# TC37XPD register map
Vendor: Infineon; Series: ATVMC; File version: 100
CPU: other r0p0, little endian, MPU, FPU, vendor SysTick, 4 interrupt priority bits
Registers are 32-bit, read-write, reset 0x0 unless marked. A register's access mark holds for its fields unless they carry their own. Offsets are from the block's base; [hi:lo] are bit positions; lines under a group give offsets from that group; {n}, {i} and the like mark numbered series; 'fields as' and 'values as' point back to an identical list.

## GTM (part 10 of 13)
Base 0xF0100000
{0xE8000+0x800*i} ATOM[{i}] (i=0..5) group
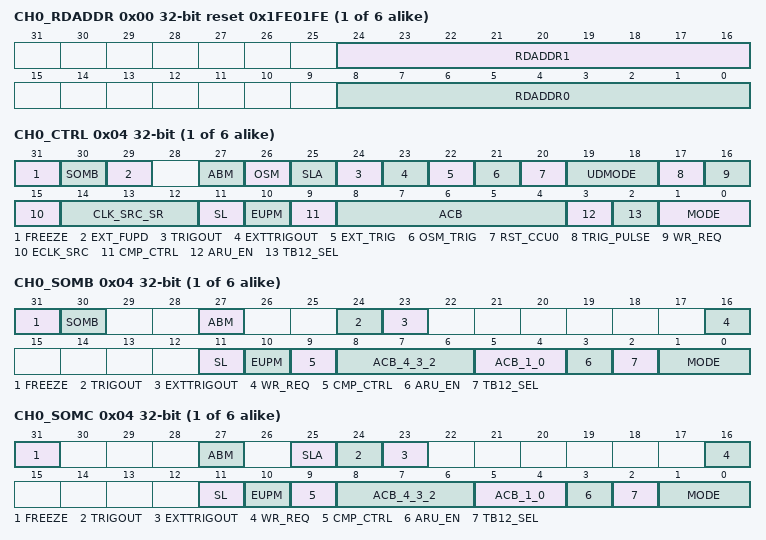
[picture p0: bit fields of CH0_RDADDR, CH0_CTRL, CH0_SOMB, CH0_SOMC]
  0x00 CH0_RDADDR reset 0x1FE01FE — ATOM0 Channel 7 ARU read address Register resetvalue={Application Reset:0x1FE01FE}
    [24:16] RDADDR1 — ARU Read address 1. Note The ATOM channel switches to this read address when requested in the ARU control bits 52 to 48 with the pattern 111 . The channel switches back to the RDADDR0 after one ARU data package was received on RDADDR1 and the compare match event is occurred. Note This read address is only applicable in SOMC mode. Note This bit field is only writable if channel is disabled.
    [8:0] RDADDR0 — ARU Read address 0. Note This read address is used by the ATOM channel to receive data from ARU immediately after the channel and ARU access is enabled see ATOM i CH x CTRL register for details . Note This bit field is only writable if channel is disabled.
  0x04 CH0_CTRL (reset mask 0xFFFFF7FF) — ATOM0 Channel 7 Control Register resetvalue={Application Reset:0x0800,Application Reset:0x0,Application Reset:0x0,Application Reset:0x0,Application Reset:0x0,Application Reset:0x0}
    [31] FREEZE — FREEZE. Note if channel is disabled and ouptut is enabled in SOMP mode with UDMODE 0b00 the output is dependng directly on SL bit independent on FREEZE mode.
    [30] SOMB — SOMB mode
    [29] EXT_FUPD — External forced update. Note This bit is only applicable in SOMP and SOMS mode.
    [27] ABM — ARU blocking mode. Note This bit is only applicable in SOMC and SOMB mode.
    [26] OSM — One shot mode. Note This bit is only applicable in SOMP and SOMS modes.
    [25] SLA — Serve last ARU communication strategy. This bit is only applicable in SOMC mode. Please note that setting of this bit has only effect when ACBI 4 2 is configured for serve last compare strategy 100 101 or 110 . When this bit is not set the captured time stamps in the shadow registers SRx are only provided after the CCU1 match occurred. The ACBO 4 3 bits always return 10 in that case. By setting this bit the ATOM channel also provides the captured time stamps after the CCU0 match event to the ARU. The ACBO 4 3 bits are set to 01 in that case. After the CCU1 match event the time stamps are captured again in the SRx registers and provided to the ARU. The ACBO 4 3 bits are set to 10 . When the data in the shadow registers after the CCU0 match was not consumed by an ARU destination and the CCU1 match occurs the data in the shadow registers is overwritten by the new captured time stamps. The ATOM channel does not request new data from the ARU when the CCU0 match values are read from an ARU destination.
    [24] TRIGOUT — Trigger output selection output signal TRIG CHx of module ATOM CHx
    [23] EXTTRIGOUT — Select TIM EXT CAPTURE x as potential output signal TRIG x
    [22] EXT_TRIG — Select TIM EXT CAPTURE x as trigger signal
    [21] OSM_TRIG — Enable trigger of one shot pulse by trigger signal OSM TRIG. Note This bit should only be set if bit OSM 1 and bit RST CCU0 0.
    [20] RST_CCU0 — Reset source of CCU0. If RST CCU0 1 and UPEN CTRLx 1 are set TRIG x 1 or TIM EXT CAPTURE x triggers also the update of work register CM0 CM1 and CLK SRC . This bit is only applicable in SOMP mode. This bit should only be set if bit OSM 0 i.e. in continuous mode .
    [19:18] UDMODE — Up down counter mode. Note This mode is only applicable in SOMP mode.
    [17] TRIG_PULSE — Trigger output pulse length of one SYS CLK period
    [16] WR_REQ — CPU Write request bit for late compare register update. Note The CPU can disable subsequent ARU read requests by the channel and can update the shadow registers with new compare values while the compare units operate on old compare values received by former ARU accesses if occurred. Note On a compare match event the WR REQ bit will be reset by hardware. Note At the point of the force update only the shadow registers SR0 and SR1 are transferred into the CM0 CM1 registers. The output action is still defined by the ACBI bit field described by the ARU together with the old compare values for CM0 CM1. Note This bit is only applicable in SOMC and SOMB mode.
    [15] ECLK_SRC — Extend CLK SRC. Note This bit is only applicable in SOMP and SOMS mode. See bit CLK SRC SR description for details.
    [14:12] CLK_SRC_SR — Actual CMU clock source SOMS shadow register for CMU clock source SOMP . If ECLK SRC 0 ECLK SRC 1 This register is a shadow register for the register CLK SRC. Thus if the CMU CLK source for PWM generation should be changed during operation the old CMU CLK has to operate until the update of the ATOM channels internal CLK SRC register by the CLK SRC SR content is done either by an end of a period or a forced update. After channel reset the selected CLK SRC value is the SYS CLK input of Global Clock Divider . To use in SOMP mode one of the CMU CLKx it is recommended to perform a forced update of CLK SRC with the value of CLK SRC SR value before with enabling the channel. In case of ECLK SRC 1 and CLK SRC SR 011 100 101 110 a force update leads to an immediate update of CM0 CM1 and CLK SRC.
    [11] SL — Initial signal level. Reset value depends on the hardware configuration chosen by silicon vendor. If the output is disabled the output ATOM OUT x is set to inverse SL independent of the ATOM channel mode. If FREEZE 0 following notes are valid In SOMP SOMI SOMS mode if the channel is disabled the internal register SOUR inside ATOM sub unit SOU is set to inverse value of SL. By enabling the channel the register SOUR is not changed. Thus if the output is enabled afterwards the output ATOM OUT x is the inverse value of SL. In SOMC mode if the channel is disabled the internal register SOUR inside ATOM sub unit SOU is set to value of SL. By enabling the channel the register SOUR is not changed. Thus if the output is enabled and the channel is disabled the output ATOM OUT x is the value of SL. If FREEZE 1 the following notes are valid If the channel is disabled the output register of SOU unit is not changed and output ATOM OUT x is not changed.
    [10] EUPM — Extended update mode. If EUPM 1 a write access to CM0 or CM1 never causes an AEI write status 10 . This bit is only applicable in SOMC and SOMB mode.
    [9] CMP_CTRL — CCUx compare strategy select. Note This bit is only applicable in SOMC mode.
    [8:4] ACB — ATOM Mode control bits. These bits have different meaning in the different ATOM channel modes. Please refer to the mode description sections. SOMI CROSSREFERENCE and CROSSREFERENCE for register description. SOMC CROSSREFERENCE and CROSSREFERENCE for register description. SOMP CROSSREFERENCE and CROSSREFERENCE for register description. SOMS CROSSREFERENCE and CROSSREFERENCE for register description. SOMB CROSSREFERENCE and CROSSREFERENCE for register description.
    [3] ARU_EN — ARU input stream enable
    [2] TB12_SEL — Select time base value TBU TS1 or TBU TS2. Note This bit is only applicable in SOMC mode.
    [1:0] MODE — ATOM channel mode select
  0x04 CH0_SOMB (reset mask 0xFFFFF7FF) — ATOM0 Channel 7 Control Register in SOMB Mode resetvalue={Application Reset:0x0800,Application Reset:0x0,Application Reset:0x0,Application Reset:0x0,Application Reset:0x0,Application Reset:0x0}
    [31] FREEZE
    [30] SOMB — SOMB SOMB mode
    [27] ABM — ARU blocking mode
    [24] TRIGOUT — Trigger output selection output signal TRIG CHx of module ATOM CHx
    [23] EXTTRIGOUT — TIM EXT CAPTURE x as potential output signal TRIG x
    [16] WR_REQ — CPU Write request bit for late compare register update. The CPU can disable subsequent ARU read requests by the channel and can update the shadow registers with new compare values while the compare units operate on old compare values received by former ARU accesses if occurred. On a compare match event the WR REQ bit will be reset by hardware. At the point of the force update only the shadow registers SR0 and SR1 are transferred into the CM0 CM1 registers. The output action is still defined by the ACBI bit field described by the ARU together with the old compare values for CM0 CM1.
    [11] SL — Initial signal level after channel enable. Reset value depends on the hardware configuration chosen by silicon vendor. If the output is disabled the output ATOM OUT x is set to inverse value of SL. If FREEZE 0 the following note is valid If the channel is disabled the output register of SOU unit is set to value of SL. If FREEZE 1 the following note is valid If the channel is disabled the output register of SOU unit is not changed and output ATOM OUT x is not changed.
    [10] EUPM — Extended update mode. If EUPM 1 and after a CCU0 compare match if ARU EN 0 written CM0 value not stored. if ARU EN 1 ARU read request is continued and CM1 is updated until CCU1 compare match. Received CM0 is not stored. This bit is only applicable in SOMC and SOMB mode.
    [9] CMP_CTRL — CCUx compare strategy select. The compare unit CCU0 or CCU1 that compares against TBU TS0 depending on CCUx control mode defined by ACB CM 4 2 always performs a greater equal comparison independent of the CMP CTRL bit.
    [8:6] ACB_4_3_2 — ATOM SOMB compare strategy. These bits are only applicable if ARU EN 0.
    [5:4] ACB_1_0 — Signal level control bits. Note These bits are only applicable if ARU EN 0.
    [3] ARU_EN — ARU Input stream enable
    [2] TB12_SEL — Select time base value TBU TS1 or TBU TS2. This bit is only applicable if three time bases are present in the GTM. Otherwise this bit is reserved.
    [1:0] MODE — ATOM channel mode select. Not used in ATOM SOMB mode.
  0x04 CH0_SOMC (reset mask 0xFFFFF7FF) — ATOM0 Channel 7 Control Register in SOMC Mode resetvalue={Application Reset:0x0800,Application Reset:0x0,Application Reset:0x0,Application Reset:0x0,Application Reset:0x0,Application Reset:0x0}
    [31] FREEZE
    [27] ABM — ARU blocking mode
    [25] SLA — Serve last ARU communication strategy. Please note that setting of this bit has only effect when ACBI 4 2 is configured for serve last compare strategy quot 100 quot quot 101 quot or quot 110 quot . When this bit is not set the captured time stamps in the shadow registers SRx are only provided after the CCU1 match occurred. The ACBO 4 3 bits always return quot 10 quot in that case. By setting this bit the ATOM channel also provides the captured time stamps after the CCU0 match event to the ARU. The ACBO 4 3 bits are set to 8220 01 8221 in that case. After the CCU1 match event the time stamps are captured again in the SRx registers and provided to the ARU. The ACBO 4 3 bits are set to 8220 10 8221 . When the data in the shadow registers after the CCU0 match was not consumed by an ARU destination and the CCU1 match occurs the data in the shadow registers is overwritten by the new captured time stamps. The ATOM channel does not request new data from the ARU when the CCU0 match values are read from an ARU destination.
    [24] TRIGOUT — TRIGOUT Trigger output selection output signal TRIG CHx of module ATOM CHx
    [23] EXTTRIGOUT — Select TIM EXT CAPTURE x as potential output signal TRIG x
    [16] WR_REQ — CPU write request bit. The CPU can disable subsequent ARU read requests by the channel and can update the shadow registers with new compare values while the compare units operate on old compare values received by former ARU accesses if occurred. On a compare match event the WR REQ bit will be reset by hardware. At the point of the force update only the shadow registers SR0 and SR1 are transferred into the CM0 CM1 registers. The output action is still defined by the ACBI bit field described by the ARU together with the old compare values for CM0 CM1.
    [11] SL — Initial signal level after channel enable. Reset value depends on the hardware configuration chosen by silicon vendor. If the output is disabled the output ATOM OUT x is set to inverse value of SL. If FREEZE 0 following note is valid If the channel is disabled the output register of SOU unit is set to value of SL. If FREEZE 1 following note is valid If the channel is disabled the output register of SOU unit is not changed and output ATOM OUT x is not changed.
    [10] EUPM — Extended Update Mode. If EUPM 1 and after a CCU0 compare match If ARU EN 0 written CM0 value not stored. If ARU EN 1 ARU read request is continued and CM1 is updated until CCU1 compare match. Received CM0 values are not stored. This bit is only applicable in SOMC and SOMB mode.
    [9] CMP_CTRL — CCUx compare strategy select. The compare unit CCU0 or CCU1 that compares against TBU TS0 depending on CCUx control mode defined by ACBI 4 2 or ACB42 always performs a greater equal comparison independent on CMP CTRL bit.
    [8:6] ACB_4_3_2 — ATOM control bits ACB 4 ACB 3 ACB 2 . Independent of ARU EN a writing of 0b111 cancels any pending CCU0 or CCU1 compare. Note These bits are defining the compare strategy only if ARU EN 0.
    [5:4] ACB_1_0 — Signal level control bits. These bits are only applicable if ARU EN 0.
    [3] ARU_EN — ARU Input stream enable
    [2] TB12_SEL — Select time base value TBU TS1 or TBU TS2. This bit is only applicable if three time bases are present in the GTM. Otherwise this bit is reserved.
    [1:0] MODE — ATOM channel mode select
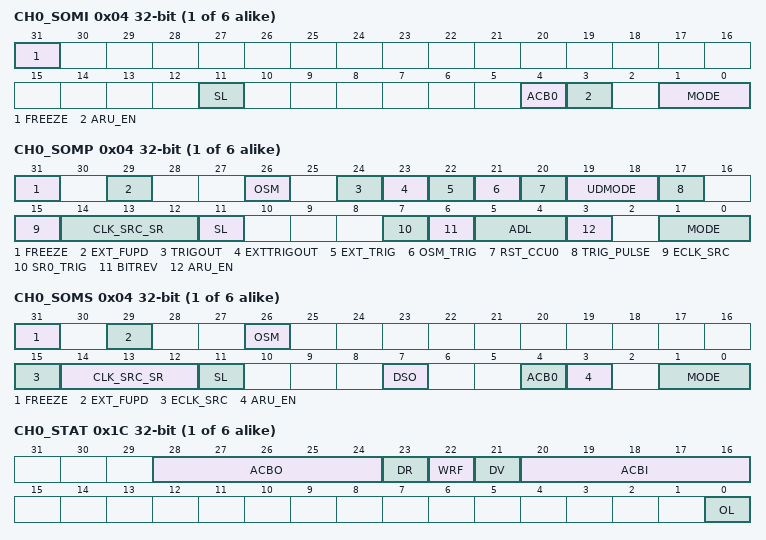
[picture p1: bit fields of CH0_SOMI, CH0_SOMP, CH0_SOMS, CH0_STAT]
  0x04 CH0_SOMI (reset mask 0xFFFFF7FF) — ATOM0 Channel 7 Control Register in SOMI Mode resetvalue={Application Reset:0x0800,Application Reset:0x0,Application Reset:0x0,Application Reset:0x0,Application Reset:0x0,Application Reset:0x0}
    [31] FREEZE
    [11] SL — Initial signal level after channel is enabled. Note Reset value depends on the hardware configuration chosen by silicon vendor. Note If the output is disabled the output ATOM OUT x is set to inverse value of SL. If FREEZE 0 following note is valid If the channel is disabled the output register of SOU unit is set to inverse value of SL. If FREEZE 1 following note is valid If the channel is disabled the output register of SOU unit is not changed and output ATOM OUT x is not changed.
    [4] ACB0 — ACB bit 0 . Note Bosch name ACB 0 .
    [3] ARU_EN — ARU Input stream enable
    [1:0] MODE — ATOM channel mode select
  0x04 CH0_SOMP (reset mask 0xFFFFF7FF) — ATOM0 Channel 7 Control Register in SOMP Mode resetvalue={Application Reset:0x0800,Application Reset:0x0,Application Reset:0x0,Application Reset:0x0,Application Reset:0x0,Application Reset:0x0}
    [31] FREEZE
    [29] EXT_FUPD — External forced update. This bit is only applicable in SOMP and SOMS mode.
    [26] OSM — One shot mode
    [24] TRIGOUT — Trigger output selection output signal TRIG CHx of module ATOM CHx
    [23] EXTTRIGOUT — Select TIM EXT CAPTURE x as potential output signal TRIG x
    [22] EXT_TRIG — Select TIM EXT CAPTURE x as trigger signal
    [21] OSM_TRIG — Enable trigger of one shot pulse by trigger signal OSM TRIG. This bit should only be set if bit OSM 1 and bit RST CCU0 0.
    [20] RST_CCU0 — Reset source of CCU0. If RST CCU0 1 and UPEN CTRLx 1 are set TRIG x 1 or TIM EXT CAPTURE x triggers also the update of work register CM0 CM1 and CLK SRC .
    [19:18] UDMODE — Up down counter mode. This mode is only applicable in SOMP mode.
    [17] TRIG_PULSE — Trigger output pulse length of one SYS CLK period
    [15] ECLK_SRC — Extend CLK SRC. See bit CLK SRC SR description for details.
    [14:12] CLK_SRC_SR — Shadow register for CMU clock source register CLK SRC. If ECLK SRC 0 ECLK SRC 1 This register is a shadow register for the register CLK SRC. Thus if the CMU CLK source for PWM generation should be changed during operation the old CMU CLK has to operate until the update of the ATOM channels internal CLK SRC register by the CLK SRC SR content is done either by an end of a period or a FORCE UPDATE. After channel reset the selected CLK SRC value is the SYS CLK input of Global Clock Divider . To use in SOMP mode one of the CMU CLKx it is recommended to perform a forced update of CLK SRC with the value of CLK SRC SR value before with enabling the channel.
    [11] SL — Signal level for pulse of PWM. Reset value depends on the hardware configuration chosen by silicon vendor. If the output is disabled the output ATOM OUT x is set to inverse value of SL FREEZE 0 the following note is valid If the channel is disabled the output register of SOU unit is set to inverse value of SL. If FREEZE 1 the following note is valid If the channel is disabled the output register of SOU unit is not changed and output ATOM OUT x is not changed.
    [7] SR0_TRIG — SR0 is used to generate a trigger on output ATOM i CH x OUT T if equal to CN0. This bit is only relevant in SOMP mode. This bit should only be set if RST CCU0 of this channel is 0.
    [6] BITREV — Bit reversing of output of counter register CN0. This bit enables the PCM mode. It is device specific in which channel the PCM mode is available. Please refer to device specific CROSSREFERENCE for this information.
    [5:4] ADL — ARU data select for SOMP. This bit field is only relevant in SOMP mode to select the ARU data source.
    [3] ARU_EN — ARU Input stream enable
    [1:0] MODE — ATOM channel mode select
  0x04 CH0_SOMS (reset mask 0xFFFFF7FF) — ATOM0 Channel 7 Control Register in SOMS Mode resetvalue={Application Reset:0x0800,Application Reset:0x0,Application Reset:0x0,Application Reset:0x0,Application Reset:0x0,Application Reset:0x0}
    [31] FREEZE
    [29] EXT_FUPD — External forced update. This bit is only applicable in SOMP and SOMS mode.
    [26] OSM — One shot mode
    [15] ECLK_SRC — Extend CLK SRC. See bit CLK SRC SR description for details.
    [14:12] CLK_SRC_SR — Shift frequency select for channel. If ECLK SRC 0 ECLK SRC 1 This register is a shadow register for the register CLK SRC. Thus if the CMU CLK source for PWM generation should be changed during operation the old CMU CLK has to operate until the update of the ATOM channels internal CLK SRC register by the CLK SRC SR content is done either by an end of a period or a FORCE UPDATE. After channel reset the selected CLK SRC value is the SYS CLK input of Global Clock Divider . To use in SOMP mode one of the CMU CLKx it is recommended to perform a forced update of CLK SRC with the value of CLK SRC SR value before with enabling the channel.
    [11] SL — Defines signal level when channel and output is disabling. Reset value depends on the hardware configuration chosen by silicon vendor. If the output is enabled the output ATOM OUT x is set to bit 0 or 23 of CM1 register. If the output is disabled the output ATOM OUT x is set to inverse value of SL. An enable or disable of the channel x has no effect on ATOM OUT x . The inverse value of SL is shifted into the CM1 register. If FREEZE 0 the following note is valid If the channel is disabled the output register of SOU unit is set to inverse value of SL. If FREEZE 1 the following note is valid If the channel is disabled the output register of SOU unit is not changed and output ATOM OUT x is not changed.
    [7] DSO — Double Shift Output. Note If DSO 1 only shift right is possible.
    [4] ACB0 — Shift direction for CM1 register. The data that has to be shifted out has to be aligned inside the CM1 register according to the defined shift direction. This bit is only applicable if ARU EN 0. If the direction ACB0 is changed the output ATOM OUT x switches immediately to the other first bit of CM1 bit 0 if ACB0 0 bit 23 if ACB0 160 160 1 .
    [3] ARU_EN — ARU Input stream enable
    [1:0] MODE — ATOM channel mode select
  0x08 CH0_SR0 — ATOM0 Channel 7 CCU0 Compare Shadow Register resetvalue={Application Reset:0x0}
    [23:0] SR0 — ATOM channel x shadow register SR0. Note The SR0 register is used as shadow register for CM0 in SOMP and SOMS modes and is used as capture register for time base TBU TS0 in SOMC mode.
  0x0C CH0_SR1 — ATOM0 Channel 7 CCU1 Compare Shadow Register resetvalue={Application Reset:0x0}
    [23:0] SR1 — ATOM channel x shadow register SR1. Note The SR1 register is used as shadow register for CM1 in SOMP and SOMS modes and is used as capture register for time base TBU TS1 or TBU TS2 when selected in ATOM i CH x CTRL register in SOMC mode.
  0x10 CH0_CM0 — ATOM0 Channel 7 CCU0 Compare Register resetvalue={Application Reset:0x0}
    [23:0] CM0 — ATOM CCU0 compare register
  0x14 CH0_CM1 — ATOM0 Channel 7 CCU1 Compare Register resetvalue={Application Reset:0x0}
    [23:0] CM1 — ATOM CCU1 compare register
  0x18 CH0_CN0 — ATOM0 Channel 7 CCU0 Counter Register resetvalue={Application Reset:0x0}
    [23:0] CN0 — ATOM CCU0 counter register
  0x1C CH0_STAT access per field — ATOM0 Channel 7 Status Register resetvalue={Application Reset:0x0}
    [28:24] ACBO ro — ATOM Internal status bits. ACBO 3 1 CCU0 Compare match occurred. ACBO 4 1 CCU1 Compare match occurred. Note These bits are only set in SOMC mode. Note ACBO is reset to 0b00000 on an update of register CM0 or CM1 via ARU or CPU . Note In SOMC mode these bits are sent as ARU control bits 52..48.
    [23] DR ro — ARU data rejected flag. Note The flag is cleared if valid data is received and stored via ARU.
    [22] WRF rw — Write request of CPU failed for late update. Note This bit is only applicable in SOMC and SOMB mode. Bit WRF can be reset by writing a 1 to it.
    [21] DV ro — Valid ARU Data stored in compare registers. Note This bit is only applicable in SOMC and SOMB mode. The CPU can determine the status of the ARU transfers with this bit. After the compare event occurred the bit is reset by hardware .
    [20:16] ACBI ro — ATOM Mode control bits. Note For ATOM SOMI SOMC SOMP and SOMS mode this register serves as a mirror for the five ARU control bits received through the ARU interface. The bits are valid when the DV bit is set. Note For SOMB mode this bit field serves as the work register of the compare strategy. It can be updated with the value of bit field ACB of register ATOM i CH x CTRL or the value of internal shadow register ACB SR.
    [0] OL ro — Actual output signal level of ATOM CHx OUT. Note Reset value is the inverted value of bit SL which depends on the hardware configuration chosen by silicon vendor.
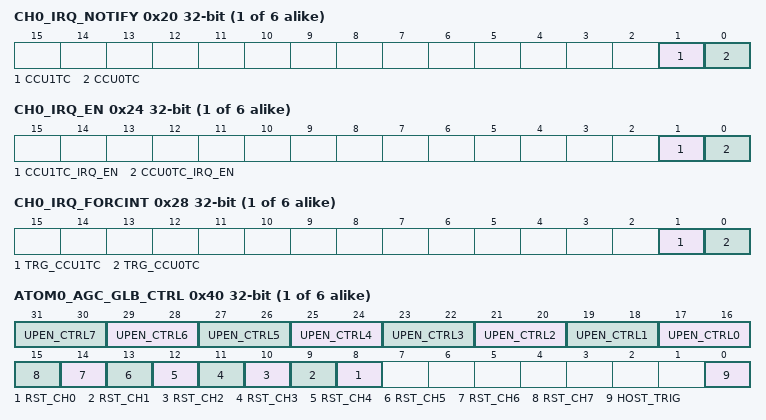
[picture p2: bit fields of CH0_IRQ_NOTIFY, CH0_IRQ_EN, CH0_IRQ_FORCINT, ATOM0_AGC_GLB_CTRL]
  0x20 CH0_IRQ_NOTIFY — ATOM0 Channel 7 Interrupt Notification Register resetvalue={Application Reset:0x0}
    [1] CCU1TC — CCU1TC CCU1 Trigger condition interrupt for channel x. The notification of the interrupt is only triggered one time after reaching the condition CN0 gt CM1. To enable re trigger of the notification first the condition CN0 lt CM1 has to be reached. Note This bit will be cleared on a CPU write access of value 1. A read access leaves the bit unchanged. Note This description differs to the description in the Bosch spec. Note If bit SR0 TRIG is set to 1 only valid in SOMP mode this interrupt notify flag is set in case of SR0 is equal to CN0 and not set in case of CM1 gt lt CN0.
    [0] CCU0TC — CCU0 Trigger condition interrupt for channel x. The notification of the interrupt is only triggered one time after reaching the condition CN0 gt CM0. To enable re trigger of the notification first the condition CN0 lt CM1 has to be reached. Note This bit will be cleared on a CPU write access of value 1. A read access leaves the bit unchanged. Note This description differs to the description in the Bosch spec.
  0x24 CH0_IRQ_EN — ATOM0 Channel 7 Interrupt Enable Register resetvalue={Application Reset:0x0}
    [1] CCU1TC_IRQ_EN — ATOM CCU1TC IRQ interrupt enable. See bit 0.
    [0] CCU0TC_IRQ_EN — ATOM CCU0TC IRQ interrupt enable
  0x28 CH0_IRQ_FORCINT — ATOM0 Channel 7 Software Interrupt Generation Register resetvalue={Application Reset:0x0}
    [1] TRG_CCU1TC — Trigger ATOM CCU1TC IRQ interrupt by software. Note This bit is cleared automatically after write. Note This bit is write protected by bit RF PROT of register GTM CTRL
    [0] TRG_CCU0TC — Trigger ATOM CCU0TC IRQ interrupt by software. Note This bit is cleared automatically after write. Note This bit is write protected by bit RF PROT of register GTM CTRL
  0x2C CH0_IRQ_MODE — ATOM0 Channel 7 Interrupt Mode Configuration Register resetvalue={Application Reset:0x0}
    [1:0] IRQ_MODE — IRQ mode selection. Note The interrupt modes are described in CROSSREFERENCE .
  0x40 ATOM0_AGC_GLB_CTRL access per field — ATOM0 AGC Global Control Register resetvalue={Application Reset:0x0}
    [2n+17:2n+16] UPEN_CTRL{n} rw (n=0..7) — ATOM channel 7 enable update of register CM0 CM1 and CLK SRC from SR0 SR1 and CLK SRC SR. Write Read
    [n+8] RST_CH{n} wo (n=0..7) — Software reset of channel 7. Note This bit is cleared automatically after write by CPU. The channel registers are set to their reset values and channel operation is stopped immediately. The output register of SOU unit is reset to inverse reset value of SL bit.
    [0] HOST_TRIG wo — Trigger request signal see AGC to update the register ENDIS STAT and OUTEN STAT. Note this flag is reset automatically after triggering the update
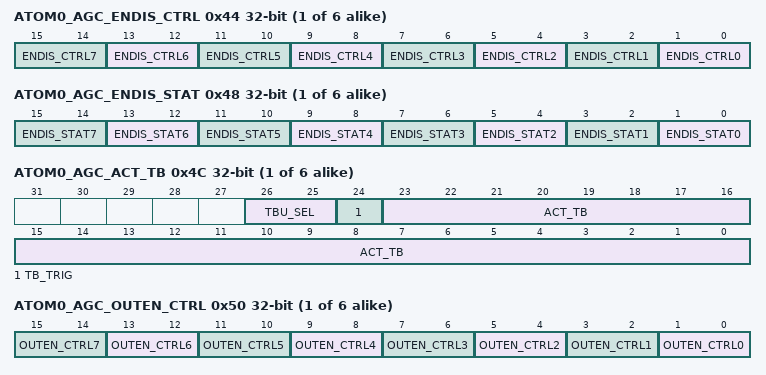
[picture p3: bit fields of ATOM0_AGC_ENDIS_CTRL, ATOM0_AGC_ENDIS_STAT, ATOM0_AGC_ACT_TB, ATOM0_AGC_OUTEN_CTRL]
  0x44 ATOM0_AGC_ENDIS_CTRL — ATOM0 AGC Enable Disable Control Register resetvalue={Application Reset:0x0}
    [2n+1:2n] ENDIS_CTRL{n} (n=0..7) — ATOM channel 7 enable disable update value. If FREEZE 0 and an ATOM channel is disabled the counter CN0 is stopped and the output register of SOU unit is set to the inverse value of control bit SL. On an enable event the counter CN0 starts counting from its current value. If FREEZE 1 and an ATOM channel is disabled the counter CN0 is stopped SOMP SOMS mode and each comparison is stopped SOMC SOMB mode . On an enable event the counter CN0 starts counting from its current value or a comparison is restarted. Write of following double bit values is possible Note If the output is disabled OUTEN x 0 the ATOM channel x output ATOM OUT x is the inverted value of bit SL.
  0x48 ATOM0_AGC_ENDIS_STAT — ATOM0 AGC Enable Disable Status Register resetvalue={Application Reset:0x0}
    [2n+1:2n] ENDIS_STAT{n} (n=0..7) — ATOM channel 7 enable disable. If FREEZE 0 and an ATOM channel is disabled the counter CN0 is stopped and the output register of SOU unit is set to the inverse value of control bit SL. On an enable event the counter CN0 starts counting from its current value. If FREEZE 1 and an ATOM channel is disabled the counter CN0 is stopped SOMP SOMS mode and each comparison is stopped SOMC SOMB mode . On an enable event the counter CN0 starts counting from its current value or a comparison is restarted.
  0x4C ATOM0_AGC_ACT_TB — ATOM0 AGC Action Time Base Register resetvalue={Application Reset:0x0}
    [26:25] TBU_SEL — Selection of time base used for comparison. Note The bit combination 0b10 is only applicable if the TBU of the device contains three time base channels. Otherwise this bit combination is also reserved. Please refer to GTM Architecture block diagram on page 3 to determine the number of channels for TBU of this device.
    [24] TB_TRIG — Set trigger request. Note This flag is reset automatically if the selected time base unit TBU TS0 or TBU TS1 or TBU TS2 if present has reached the value ACT TB and the update of the register was triggered.
    [23:0] ACT_TB — Time base value. Specifies the signed compare value with selected signal TBU TS x x 0..2. If selected TBU TS x value is in the interval ACT TB 007FFFFFh ACT TB the event is in the past and the trigger is generated immediately. Otherwise the event is in the future and the trigger is generated if selected TBU TS x is equal to ACT TB.
  0x50 ATOM0_AGC_OUTEN_CTRL — ATOM0 AGC Output Enable Control Register resetvalue={Application Reset:0x0}
    [2n+1:2n] OUTEN_CTRL{n} (n=0..7) — Output ATOM OUT7 enable disable update value. Write of following double bit values is possible Note If the channel is disabled ENDIS 0 0 or the output is disabled OUTEN 0 0 the TOM channel 0 output ATOM OUT 0 is the inverted value of bit SL.
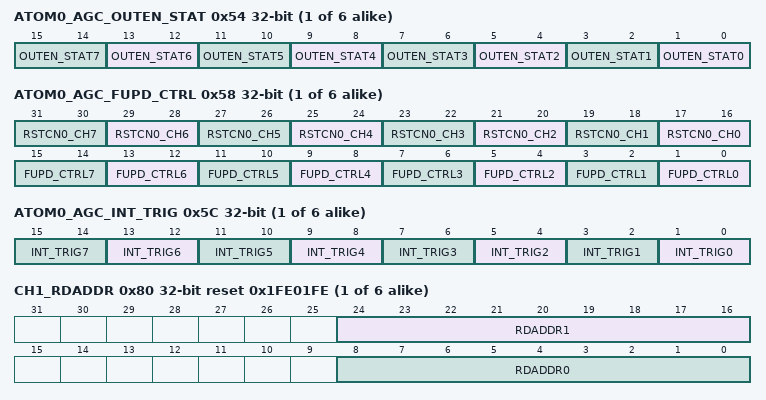
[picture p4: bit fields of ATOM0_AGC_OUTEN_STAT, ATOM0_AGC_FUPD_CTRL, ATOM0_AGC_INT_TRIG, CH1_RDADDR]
  0x54 ATOM0_AGC_OUTEN_STAT — ATOM0 AGC Output Enable Status Register resetvalue={Application Reset:0x0}
    [2n+1:2n] OUTEN_STAT{n} (n=0..7) — Control status of output ATOM OUT7. Write Read
  0x58 ATOM0_AGC_FUPD_CTRL — ATOM0 AGC Force Update Control Register resetvalue={Application Reset:0x0}
    [2n+17:2n+16] RSTCN0_CH{n} (n=0..7) — Reset CN0 of channel 7 on force update event. If enabled reset CN0 triggered by HOST TRIG ACT TB compare match or internal trigger. Write Read
    [2n+1:2n] FUPD_CTRL{n} (n=0..7) — Force update of ATOM channel 7 operation registers. If enabled force update of register CM0 CM1 and CLK SRC triggered by HOST TRIG ACT TB compare match or internal trigger. Write Read Note In SOMP mode the force update request is stored and executed synchronized to the selected CMU CLK. In all other modes the force update request is executed immediately. Note In SOMP mode in case of ECLK SRC 1 and CLK SRC SR 0b011 0b100 0b101 0b110 a force update leads to an immediate update of CM0 CM1 and CLK SRC.
  0x5C ATOM0_AGC_INT_TRIG — ATOM0 AGC Internal Trigger Control Register resetvalue={Application Reset:0x0}
    [2n+1:2n] INT_TRIG{n} (n=0..7) — Select input signal TRIG 7 as a trigger source. Write Read
  0x80 CH1_RDADDR reset 0x1FE01FE — ATOM0 Channel 7 ARU read address Register resetvalue={Application Reset:0x1FE01FE}
    fields as ATOM[0].CH0_RDADDR
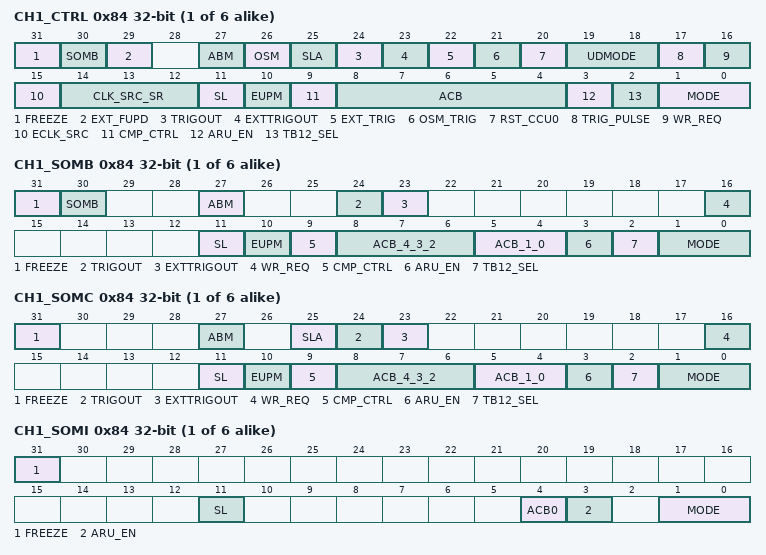
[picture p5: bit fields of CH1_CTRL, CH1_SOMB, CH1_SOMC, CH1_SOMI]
  0x84 CH1_CTRL (reset mask 0xFFFFF7FF) — ATOM0 Channel 7 Control Register resetvalue={Application Reset:0x0800,Application Reset:0x0,Application Reset:0x0,Application Reset:0x0,Application Reset:0x0,Application Reset:0x0}
    fields as ATOM[0].CH0_CTRL
  0x84 CH1_SOMB (reset mask 0xFFFFF7FF) — ATOM0 Channel 7 Control Register in SOMB Mode resetvalue={Application Reset:0x0800,Application Reset:0x0,Application Reset:0x0,Application Reset:0x0,Application Reset:0x0,Application Reset:0x0}
    fields as ATOM[0].CH0_SOMB
  0x84 CH1_SOMC (reset mask 0xFFFFF7FF) — ATOM0 Channel 7 Control Register in SOMC Mode resetvalue={Application Reset:0x0800,Application Reset:0x0,Application Reset:0x0,Application Reset:0x0,Application Reset:0x0,Application Reset:0x0}
    fields as ATOM[0].CH0_SOMC
  0x84 CH1_SOMI (reset mask 0xFFFFF7FF) — ATOM0 Channel 7 Control Register in SOMI Mode resetvalue={Application Reset:0x0800,Application Reset:0x0,Application Reset:0x0,Application Reset:0x0,Application Reset:0x0,Application Reset:0x0}
    fields as ATOM[0].CH0_SOMI
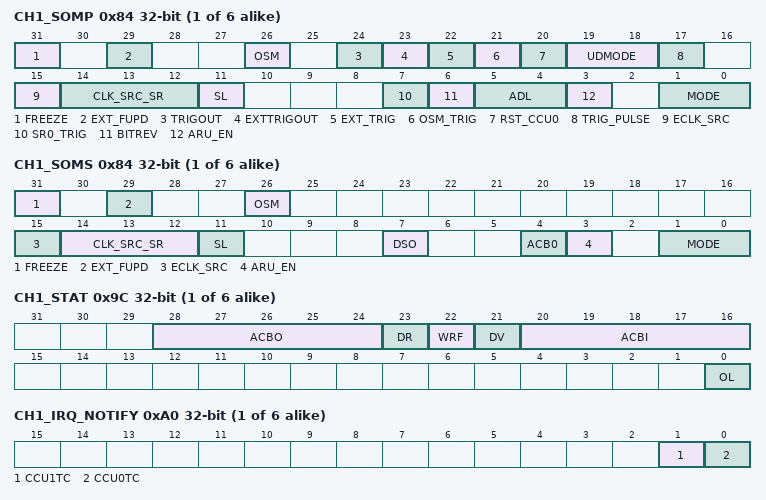
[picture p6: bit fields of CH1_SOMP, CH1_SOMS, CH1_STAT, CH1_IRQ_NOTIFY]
  0x84 CH1_SOMP (reset mask 0xFFFFF7FF) — ATOM0 Channel 7 Control Register in SOMP Mode resetvalue={Application Reset:0x0800,Application Reset:0x0,Application Reset:0x0,Application Reset:0x0,Application Reset:0x0,Application Reset:0x0}
    fields as ATOM[0].CH0_SOMP
  0x84 CH1_SOMS (reset mask 0xFFFFF7FF) — ATOM0 Channel 7 Control Register in SOMS Mode resetvalue={Application Reset:0x0800,Application Reset:0x0,Application Reset:0x0,Application Reset:0x0,Application Reset:0x0,Application Reset:0x0}
    fields as ATOM[0].CH0_SOMS
  0x88 CH1_SR0 — ATOM0 Channel 7 CCU0 Compare Shadow Register resetvalue={Application Reset:0x0}
    fields as ATOM[0].CH0_SR0
  0x8C CH1_SR1 — ATOM0 Channel 7 CCU1 Compare Shadow Register resetvalue={Application Reset:0x0}
    fields as ATOM[0].CH0_SR1
  0x90 CH1_CM0 — ATOM0 Channel 7 CCU0 Compare Register resetvalue={Application Reset:0x0}
    [23:0] CM0 — ATOM CCU0 compare register
  0x94 CH1_CM1 — ATOM0 Channel 7 CCU1 Compare Register resetvalue={Application Reset:0x0}
    [23:0] CM1 — ATOM CCU1 compare register
  0x98 CH1_CN0 — ATOM0 Channel 7 CCU0 Counter Register resetvalue={Application Reset:0x0}
    [23:0] CN0 — ATOM CCU0 counter register
  0x9C CH1_STAT access per field — ATOM0 Channel 7 Status Register resetvalue={Application Reset:0x0}
    fields as ATOM[0].CH0_STAT
  0xA0 CH1_IRQ_NOTIFY — ATOM0 Channel 7 Interrupt Notification Register resetvalue={Application Reset:0x0}
    fields as ATOM[0].CH0_IRQ_NOTIFY
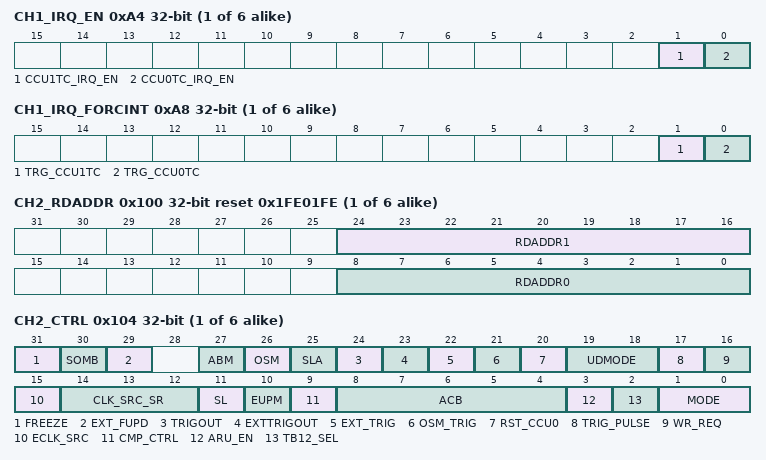
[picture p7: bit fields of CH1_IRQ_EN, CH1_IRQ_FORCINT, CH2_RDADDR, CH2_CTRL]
  0xA4 CH1_IRQ_EN — ATOM0 Channel 7 Interrupt Enable Register resetvalue={Application Reset:0x0}
    fields as ATOM[0].CH0_IRQ_EN
  0xA8 CH1_IRQ_FORCINT — ATOM0 Channel 7 Software Interrupt Generation Register resetvalue={Application Reset:0x0}
    fields as ATOM[0].CH0_IRQ_FORCINT
  0xAC CH1_IRQ_MODE — ATOM0 Channel 7 Interrupt Mode Configuration Register resetvalue={Application Reset:0x0}
    fields as ATOM[0].CH0_IRQ_MODE
  0x100 CH2_RDADDR reset 0x1FE01FE — ATOM0 Channel 7 ARU read address Register resetvalue={Application Reset:0x1FE01FE}
    fields as ATOM[0].CH0_RDADDR
  0x104 CH2_CTRL (reset mask 0xFFFFF7FF) — ATOM0 Channel 7 Control Register resetvalue={Application Reset:0x0800,Application Reset:0x0,Application Reset:0x0,Application Reset:0x0,Application Reset:0x0,Application Reset:0x0}
    fields as ATOM[0].CH0_CTRL
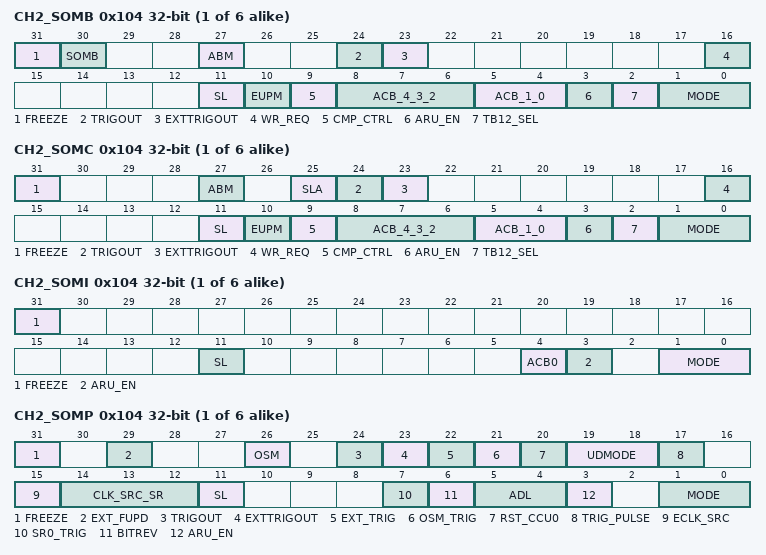
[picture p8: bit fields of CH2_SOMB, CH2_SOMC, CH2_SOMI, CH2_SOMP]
  0x104 CH2_SOMB (reset mask 0xFFFFF7FF) — ATOM0 Channel 7 Control Register in SOMB Mode resetvalue={Application Reset:0x0800,Application Reset:0x0,Application Reset:0x0,Application Reset:0x0,Application Reset:0x0,Application Reset:0x0}
    fields as ATOM[0].CH0_SOMB
  0x104 CH2_SOMC (reset mask 0xFFFFF7FF) — ATOM0 Channel 7 Control Register in SOMC Mode resetvalue={Application Reset:0x0800,Application Reset:0x0,Application Reset:0x0,Application Reset:0x0,Application Reset:0x0,Application Reset:0x0}
    fields as ATOM[0].CH0_SOMC
  0x104 CH2_SOMI (reset mask 0xFFFFF7FF) — ATOM0 Channel 7 Control Register in SOMI Mode resetvalue={Application Reset:0x0800,Application Reset:0x0,Application Reset:0x0,Application Reset:0x0,Application Reset:0x0,Application Reset:0x0}
    fields as ATOM[0].CH0_SOMI
  0x104 CH2_SOMP (reset mask 0xFFFFF7FF) — ATOM0 Channel 7 Control Register in SOMP Mode resetvalue={Application Reset:0x0800,Application Reset:0x0,Application Reset:0x0,Application Reset:0x0,Application Reset:0x0,Application Reset:0x0}
    fields as ATOM[0].CH0_SOMP
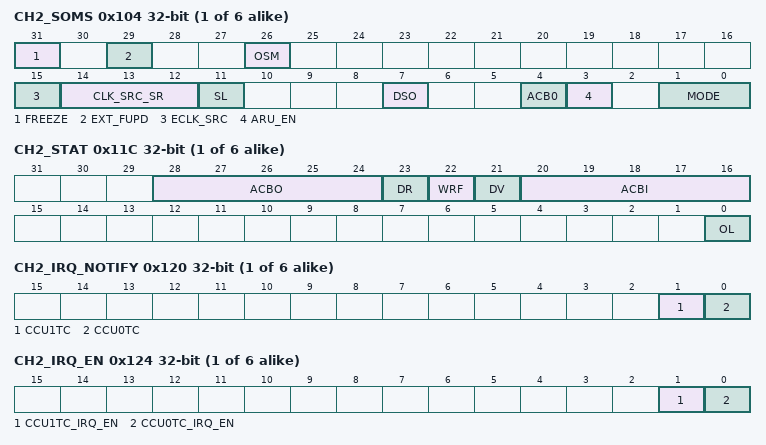
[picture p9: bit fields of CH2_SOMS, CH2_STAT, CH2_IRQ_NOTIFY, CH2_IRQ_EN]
  0x104 CH2_SOMS (reset mask 0xFFFFF7FF) — ATOM0 Channel 7 Control Register in SOMS Mode resetvalue={Application Reset:0x0800,Application Reset:0x0,Application Reset:0x0,Application Reset:0x0,Application Reset:0x0,Application Reset:0x0}
    fields as ATOM[0].CH0_SOMS
  0x108 CH2_SR0 — ATOM0 Channel 7 CCU0 Compare Shadow Register resetvalue={Application Reset:0x0}
    fields as ATOM[0].CH0_SR0
  0x10C CH2_SR1 — ATOM0 Channel 7 CCU1 Compare Shadow Register resetvalue={Application Reset:0x0}
    fields as ATOM[0].CH0_SR1
  0x110 CH2_CM0 — ATOM0 Channel 7 CCU0 Compare Register resetvalue={Application Reset:0x0}
    [23:0] CM0 — ATOM CCU0 compare register
  0x114 CH2_CM1 — ATOM0 Channel 7 CCU1 Compare Register resetvalue={Application Reset:0x0}
    [23:0] CM1 — ATOM CCU1 compare register
  0x118 CH2_CN0 — ATOM0 Channel 7 CCU0 Counter Register resetvalue={Application Reset:0x0}
    [23:0] CN0 — ATOM CCU0 counter register
  0x11C CH2_STAT access per field — ATOM0 Channel 7 Status Register resetvalue={Application Reset:0x0}
    fields as ATOM[0].CH0_STAT
  0x120 CH2_IRQ_NOTIFY — ATOM0 Channel 7 Interrupt Notification Register resetvalue={Application Reset:0x0}
    fields as ATOM[0].CH0_IRQ_NOTIFY
  0x124 CH2_IRQ_EN — ATOM0 Channel 7 Interrupt Enable Register resetvalue={Application Reset:0x0}
    fields as ATOM[0].CH0_IRQ_EN
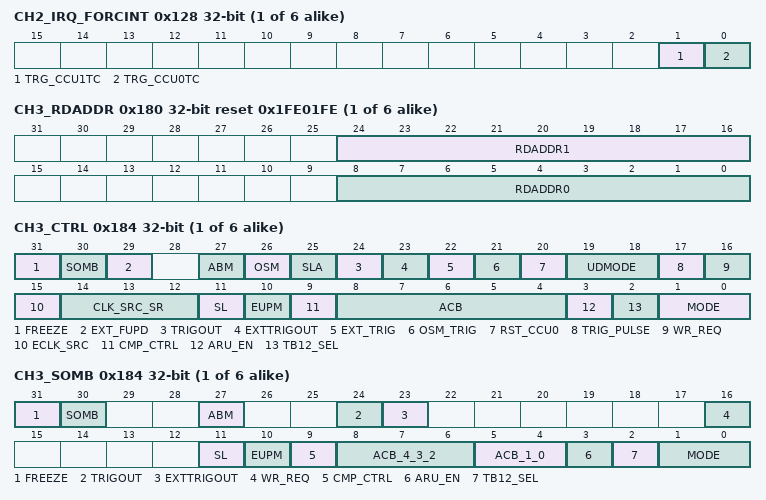
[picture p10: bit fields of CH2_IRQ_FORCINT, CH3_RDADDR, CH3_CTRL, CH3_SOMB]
  0x128 CH2_IRQ_FORCINT — ATOM0 Channel 7 Software Interrupt Generation Register resetvalue={Application Reset:0x0}
    fields as ATOM[0].CH0_IRQ_FORCINT
  0x12C CH2_IRQ_MODE — ATOM0 Channel 7 Interrupt Mode Configuration Register resetvalue={Application Reset:0x0}
    fields as ATOM[0].CH0_IRQ_MODE
  0x180 CH3_RDADDR reset 0x1FE01FE — ATOM0 Channel 7 ARU read address Register resetvalue={Application Reset:0x1FE01FE}
    fields as ATOM[0].CH0_RDADDR
  0x184 CH3_CTRL (reset mask 0xFFFFF7FF) — ATOM0 Channel 7 Control Register resetvalue={Application Reset:0x0800,Application Reset:0x0,Application Reset:0x0,Application Reset:0x0,Application Reset:0x0,Application Reset:0x0}
    fields as ATOM[0].CH0_CTRL
  0x184 CH3_SOMB (reset mask 0xFFFFF7FF) — ATOM0 Channel 7 Control Register in SOMB Mode resetvalue={Application Reset:0x0800,Application Reset:0x0,Application Reset:0x0,Application Reset:0x0,Application Reset:0x0,Application Reset:0x0}
    fields as ATOM[0].CH0_SOMB
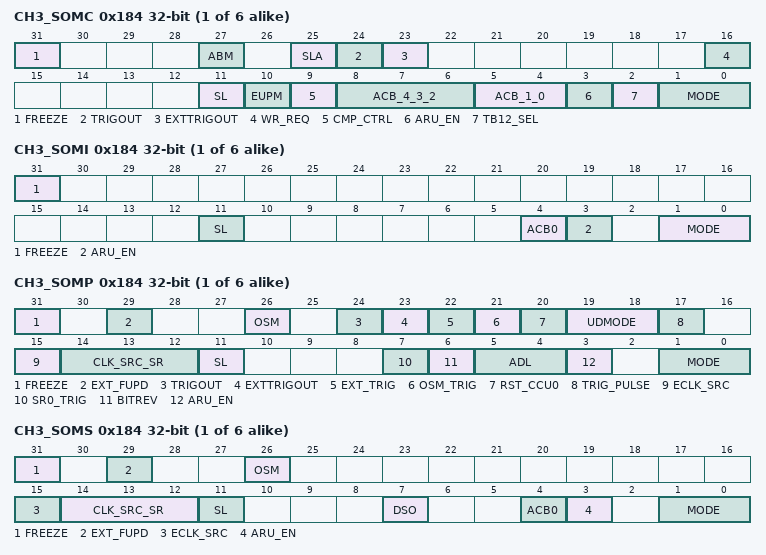
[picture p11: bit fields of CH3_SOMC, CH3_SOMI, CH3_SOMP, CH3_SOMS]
  0x184 CH3_SOMC (reset mask 0xFFFFF7FF) — ATOM0 Channel 7 Control Register in SOMC Mode resetvalue={Application Reset:0x0800,Application Reset:0x0,Application Reset:0x0,Application Reset:0x0,Application Reset:0x0,Application Reset:0x0}
    fields as ATOM[0].CH0_SOMC
  0x184 CH3_SOMI (reset mask 0xFFFFF7FF) — ATOM0 Channel 7 Control Register in SOMI Mode resetvalue={Application Reset:0x0800,Application Reset:0x0,Application Reset:0x0,Application Reset:0x0,Application Reset:0x0,Application Reset:0x0}
    fields as ATOM[0].CH0_SOMI
  0x184 CH3_SOMP (reset mask 0xFFFFF7FF) — ATOM0 Channel 7 Control Register in SOMP Mode resetvalue={Application Reset:0x0800,Application Reset:0x0,Application Reset:0x0,Application Reset:0x0,Application Reset:0x0,Application Reset:0x0}
    fields as ATOM[0].CH0_SOMP
  0x184 CH3_SOMS (reset mask 0xFFFFF7FF) — ATOM0 Channel 7 Control Register in SOMS Mode resetvalue={Application Reset:0x0800,Application Reset:0x0,Application Reset:0x0,Application Reset:0x0,Application Reset:0x0,Application Reset:0x0}
    fields as ATOM[0].CH0_SOMS
  0x188 CH3_SR0 — ATOM0 Channel 7 CCU0 Compare Shadow Register resetvalue={Application Reset:0x0}
    fields as ATOM[0].CH0_SR0
  0x18C CH3_SR1 — ATOM0 Channel 7 CCU1 Compare Shadow Register resetvalue={Application Reset:0x0}
    fields as ATOM[0].CH0_SR1
  0x190 CH3_CM0 — ATOM0 Channel 7 CCU0 Compare Register resetvalue={Application Reset:0x0}
    [23:0] CM0 — ATOM CCU0 compare register
  0x194 CH3_CM1 — ATOM0 Channel 7 CCU1 Compare Register resetvalue={Application Reset:0x0}
    [23:0] CM1 — ATOM CCU1 compare register
  0x198 CH3_CN0 — ATOM0 Channel 7 CCU0 Counter Register resetvalue={Application Reset:0x0}
    [23:0] CN0 — ATOM CCU0 counter register
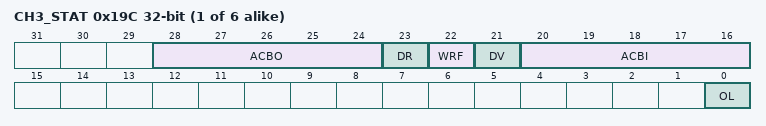
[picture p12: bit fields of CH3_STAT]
  0x19C CH3_STAT access per field — ATOM0 Channel 7 Status Register resetvalue={Application Reset:0x0}
    fields as ATOM[0].CH0_STAT
